AUTOSAR XML (schema 4-2-1)
package /AUTOSAR_EcuM/SwComponentTypes
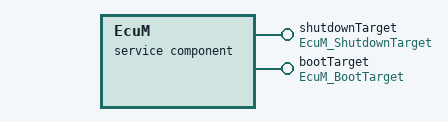
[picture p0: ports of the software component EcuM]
  service sw component type EcuM
    provide port shutdownTarget: provided-interface=EcuM_ShutdownTarget
    provide port bootTarget: provided-interface=EcuM_BootTarget
    behavior EcuMIntBeh: handle-termination-and-restart=NO-SUPPORT
      9 x operation invoked event:
        EV_SelShutdownTarget: start-on-event=RE_SelectShutdownTarget, operation=shutdownTarget.SelectShutdownTarget
        EV_GetShutdownTarget: start-on-event=RE_GetShutdownTarget, operation=shutdownTarget.GetShutdownTarget
        EV_GetLastShutdownTarget: start-on-event=RE_GetLastShutdownTarget, operation=shutdownTarget.GetLastShutdownTarget
        EV_GetMostRecentShutdown: start-on-event=RE_GetMostRecentShutdown, operation=shutdownTarget.GetMostRecentShutdown
        EV_GetNextRecentShutdown: start-on-event=RE_GetNextRecentShutdown, operation=shutdownTarget.GetNextRecentShutdown
        EV_SelectShutdownCause: start-on-event=RE_SelectShutdownCause, operation=shutdownTarget.SelectShutdownCause
        EV_GetShutdownCause: start-on-event=RE_GetShutdownCause, operation=shutdownTarget.GetShutdownCause
        EV_SelBootTarget: start-on-event=RE_SelectBootTarget, operation=bootTarget.SelectBootTarget
        EV_GetBootTarget: start-on-event=RE_GetBootTarget, operation=bootTarget.GetBootTarget
      10 x runnable:
        RE_SelectShutdownTarget: can-be-invoked-concurrently=true, symbol=EcuM_SelectShutdownTarget
        RE_GetShutdownTarget: can-be-invoked-concurrently=true, symbol=EcuM_Rte_GetShutdownTarget
        RE_GetLastShutdownTarget: can-be-invoked-concurrently=true, symbol=EcuM_Rte_GetLastShutdownTarget
        RE_GetMostRecentShutdown: can-be-invoked-concurrently=true, symbol=EcuM_Rte_GetMostRecentShutdown
        RE_GetNextRecentShutdown: can-be-invoked-concurrently=true, symbol=EcuM_Rte_GetNextRecentShutdown
        RE_SelectShutdownCause: can-be-invoked-concurrently=true, symbol=EcuM_Rte_SelectShutdownCause
        RE_GetShutdownCause: can-be-invoked-concurrently=true, symbol=EcuM_Rte_GetShutdownCause
        RE_SelectBootTarget: can-be-invoked-concurrently=true, symbol=EcuM_Rte_SelectBootTarget
        RE_GetBootTarget: can-be-invoked-concurrently=true, symbol=EcuM_Rte_GetBootTarget
        RE_Main: symbol=EcuM_MainFunction
package /EB_EcuM/SwcImplementations
  swc implementation EcuMImpl: programming-language=C, sw-version=1.0.0, vendor-id=1, behavior=EcuMIntBeh
    code-descriptors:
      code Code: artifact-descriptors=autosar-engineering-object={short-label=EngObject, category=SWSRC}
    resource consumption Resources
      memory section CODE: sw-addrmethod=CODE
